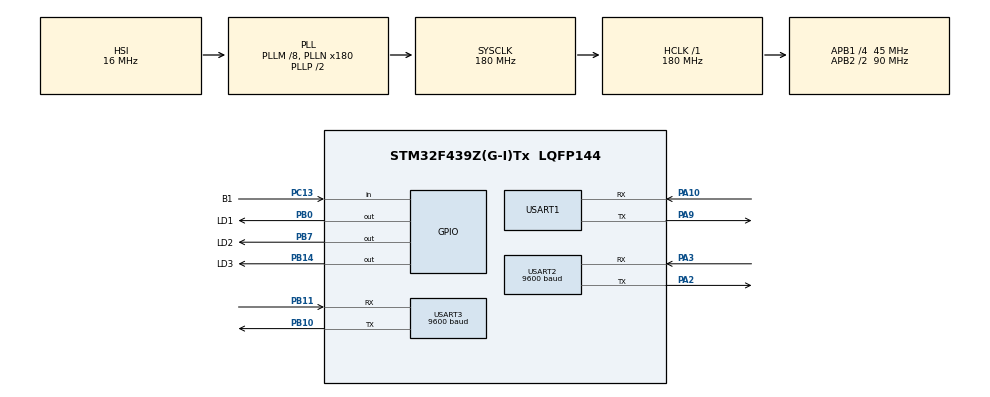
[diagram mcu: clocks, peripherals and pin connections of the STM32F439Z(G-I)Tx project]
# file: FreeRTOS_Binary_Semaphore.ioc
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FREERTOS.BinarySemaphores01=BinSem,Dynamic,NULL
FREERTOS.Tasks01=NormalTask,24,128,StartNormalTask,Default,NULL,Dynamic,NULL,NULL;HighTask,32,128,StartHighTask,Default,NULL,Dynamic,NULL,NULL;LowTask,8,128,StartLowTask,Default,NULL,Dynamic,NULL,NULL
Mcu.Family=STM32F4
Mcu.Name=STM32F439Z(G-I)Tx
Mcu.Package=LQFP144
NVIC.PriorityGroup=NVIC_PRIORITYGROUP_4
NVIC.TIM6_DAC_IRQn=true\:0\:0\:false\:false\:true\:false\:false\:true
NVIC.TimeBase=TIM6_DAC_IRQn
NVIC.TimeBaseIP=TIM6
PA10.Mode=Asynchronous
PA10.Signal=USART1_RX
PA2.Mode=Asynchronous
PA2.Signal=USART2_TX
PA3.Mode=Asynchronous
PA3.Signal=USART2_RX
PA9.Mode=Asynchronous
PA9.Signal=USART1_TX
PB0.GPIO_Label=LD1
PB0.Signal=GPIO_Output
PB10.Mode=Asynchronous
PB10.Signal=USART3_TX
PB11.Mode=Asynchronous
PB11.Signal=USART3_RX
PB14.GPIO_Label=LD3
PB14.Signal=GPIO_Output
PB7.GPIO_Label=LD2
PB7.Signal=GPIO_Output
PC13.GPIO_Label=B1
PC13.Signal=GPIO_Input
PH0/OSC_IN.Mode=HSE-External-Oscillator
PH0/OSC_IN.Signal=RCC_OSC_IN
PH1/OSC_OUT.Mode=HSE-External-Oscillator
PH1/OSC_OUT.Signal=RCC_OSC_OUT
ProjectManager.HeapSize=0x200
ProjectManager.StackSize=0x400
ProjectManager.TargetToolchain=STM32CubeIDE
RCC.48MHZClocksFreq_Value=90000000
RCC.AHBFreq_Value=180000000
RCC.APB1CLKDivider=RCC_HCLK_DIV4
RCC.APB1Freq_Value=45000000
RCC.APB1TimFreq_Value=90000000
RCC.APB2CLKDivider=RCC_HCLK_DIV2
RCC.APB2Freq_Value=90000000
RCC.APB2TimFreq_Value=180000000
RCC.CortexFreq_Value=180000000
RCC.HCLKFreq_Value=180000000
RCC.HSE_VALUE=25000000
RCC.HSI_VALUE=16000000
RCC.LSE_VALUE=32768
RCC.PLLM=8
RCC.PLLN=180
RCC.SYSCLKFreq_VALUE=180000000
RCC.SYSCLKSource=RCC_SYSCLKSOURCE_PLLCLK
RCC.VCOOutputFreq_Value=360000000
USART1.VirtualMode=VM_ASYNC
USART2.BaudRate=9600
USART2.VirtualMode=VM_ASYNC
USART3.BaudRate=9600
USART3.VirtualMode=VM_ASYNC
VP_FREERTOS_VS_CMSIS_V2.Mode=CMSIS_V2
VP_SYS_VS_tim6.Mode=TIM6
board=custom

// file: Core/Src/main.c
/* USER CODE BEGIN Header */
/**
  ******************************************************************************
  * @file           : main.c
  * @brief          : Main program body
  ******************************************************************************
  * @attention
  *
  * <h2><center>&copy; Copyright (c) 2021 STMicroelectronics.
  * All rights reserved.</center></h2>
  *
  * This software component is licensed by ST under BSD 3-Clause license,
  * the "License"; You may not use this file except in compliance with the
  * License. You may obtain a copy of the License at:
  *                        opensource.org/licenses/BSD-3-Clause
  *
  ******************************************************************************
  */
/* USER CODE END Header */

#include "main.h"
#include "cmsis_os.h"

/* USER CODE BEGIN Includes */
#include <string.h>
/* USER CODE END Includes */

UART_HandleTypeDef huart1;
UART_HandleTypeDef huart2;
UART_HandleTypeDef huart3;

/* Definitions for NormalTask */
osThreadId_t NormalTaskHandle;
const osThreadAttr_t NormalTask_attributes = {
  .name = "NormalTask",
  .priority = (osPriority_t) osPriorityNormal,
  .stack_size = 128 * 4
};
/* Definitions for HighTask */
osThreadId_t HighTaskHandle;
const osThreadAttr_t HighTask_attributes = {
  .name = "HighTask",
  .priority = (osPriority_t) osPriorityAboveNormal,
  .stack_size = 128 * 4
};
/* Definitions for LowTask */
osThreadId_t LowTaskHandle;
const osThreadAttr_t LowTask_attributes = {
  .name = "LowTask",
  .priority = (osPriority_t) osPriorityLow,
  .stack_size = 128 * 4
};
/* Definitions for BinSem */
osSemaphoreId_t BinSemHandle;
const osSemaphoreAttr_t BinSem_attributes = {
  .name = "BinSem"
};

void SystemClock_Config(void);
static void MX_GPIO_Init(void);
static void MX_USART2_UART_Init(void);
static void MX_USART3_UART_Init(void);
static void MX_USART1_UART_Init(void);
void StartNormalTask(void *argument);
void StartHighTask(void *argument);
void StartLowTask(void *argument);

int main(void)
{

  /* MCU Configuration--------------------------------------------------------*/

  /* Reset of all peripherals, Initializes the Flash interface and the Systick. */
  HAL_Init();

  /* Configure the system clock */
  SystemClock_Config();

  /* Initialize all configured peripherals */
  MX_GPIO_Init();
  MX_USART2_UART_Init();
  MX_USART3_UART_Init();
  MX_USART1_UART_Init();

  /* Init scheduler */
  osKernelInitialize();

  /* Create the semaphores(s) */
  /* creation of BinSem */
  BinSemHandle = osSemaphoreNew(1, 1, &BinSem_attributes);

  /* Create the thread(s) */
  /* creation of NormalTask */
  NormalTaskHandle = osThreadNew(StartNormalTask, NULL, &NormalTask_attributes);

  /* creation of HighTask */
  HighTaskHandle = osThreadNew(StartHighTask, NULL, &HighTask_attributes);

  /* creation of LowTask */
  LowTaskHandle = osThreadNew(StartLowTask, NULL, &LowTask_attributes);

  /* Start scheduler */
  osKernelStart();

  /* We should never get here as control is now taken by the scheduler */
  /* Infinite loop */
  while (1)
  {

  }
}

void SystemClock_Config(void)
{
  RCC_OscInitTypeDef RCC_OscInitStruct = {0};
  RCC_ClkInitTypeDef RCC_ClkInitStruct = {0};

  /** Configure the main internal regulator output voltage
  */
  __HAL_RCC_PWR_CLK_ENABLE();
  __HAL_PWR_VOLTAGESCALING_CONFIG(PWR_REGULATOR_VOLTAGE_SCALE1);
  /** Initializes the CPU, AHB and APB busses clocks
  */
  RCC_OscInitStruct.OscillatorType = RCC_OSCILLATORTYPE_HSI;
  RCC_OscInitStruct.HSIState = RCC_HSI_ON;
  RCC_OscInitStruct.HSICalibrationValue = RCC_HSICALIBRATION_DEFAULT;
  RCC_OscInitStruct.PLL.PLLState = RCC_PLL_ON;
  RCC_OscInitStruct.PLL.PLLSource = RCC_PLLSOURCE_HSI;
  RCC_OscInitStruct.PLL.PLLM = 8;
  RCC_OscInitStruct.PLL.PLLN = 180;
  RCC_OscInitStruct.PLL.PLLP = RCC_PLLP_DIV2;
  RCC_OscInitStruct.PLL.PLLQ = 4;
  if (HAL_RCC_OscConfig(&RCC_OscInitStruct) != HAL_OK)
  {
    Error_Handler();
  }
  /** Activate the Over-Drive mode
  */
  if (HAL_PWREx_EnableOverDrive() != HAL_OK)
  {
    Error_Handler();
  }
  /** Initializes the CPU, AHB and APB busses clocks
  */
  RCC_ClkInitStruct.ClockType = RCC_CLOCKTYPE_HCLK|RCC_CLOCKTYPE_SYSCLK
                              |RCC_CLOCKTYPE_PCLK1|RCC_CLOCKTYPE_PCLK2;
  RCC_ClkInitStruct.SYSCLKSource = RCC_SYSCLKSOURCE_PLLCLK;
  RCC_ClkInitStruct.AHBCLKDivider = RCC_SYSCLK_DIV1;
  RCC_ClkInitStruct.APB1CLKDivider = RCC_HCLK_DIV4;
  RCC_ClkInitStruct.APB2CLKDivider = RCC_HCLK_DIV2;

  if (HAL_RCC_ClockConfig(&RCC_ClkInitStruct, FLASH_LATENCY_5) != HAL_OK)
  {
    Error_Handler();
  }
}

static void MX_USART1_UART_Init(void)
{

  huart1.Instance = USART1;
  huart1.Init.BaudRate = 115200;
  huart1.Init.WordLength = UART_WORDLENGTH_8B;
  huart1.Init.StopBits = UART_STOPBITS_1;
  huart1.Init.Parity = UART_PARITY_NONE;
  huart1.Init.Mode = UART_MODE_TX_RX;
  huart1.Init.HwFlowCtl = UART_HWCONTROL_NONE;
  huart1.Init.OverSampling = UART_OVERSAMPLING_16;
  if (HAL_UART_Init(&huart1) != HAL_OK)
  {
    Error_Handler();
  }

}

static void MX_USART2_UART_Init(void)
{

  huart2.Instance = USART2;
  huart2.Init.BaudRate = 9600;
  huart2.Init.WordLength = UART_WORDLENGTH_8B;
  huart2.Init.StopBits = UART_STOPBITS_1;
  huart2.Init.Parity = UART_PARITY_NONE;
  huart2.Init.Mode = UART_MODE_TX_RX;
  huart2.Init.HwFlowCtl = UART_HWCONTROL_NONE;
  huart2.Init.OverSampling = UART_OVERSAMPLING_16;
  if (HAL_UART_Init(&huart2) != HAL_OK)
  {
    Error_Handler();
  }

}

static void MX_USART3_UART_Init(void)
{

  huart3.Instance = USART3;
  huart3.Init.BaudRate = 9600;
  huart3.Init.WordLength = UART_WORDLENGTH_8B;
  huart3.Init.StopBits = UART_STOPBITS_1;
  huart3.Init.Parity = UART_PARITY_NONE;
  huart3.Init.Mode = UART_MODE_TX_RX;
  huart3.Init.HwFlowCtl = UART_HWCONTROL_NONE;
  huart3.Init.OverSampling = UART_OVERSAMPLING_16;
  if (HAL_UART_Init(&huart3) != HAL_OK)
  {
    Error_Handler();
  }

}

static void MX_GPIO_Init(void)
{
  GPIO_InitTypeDef GPIO_InitStruct = {0};

  /* GPIO Ports Clock Enable */
  __HAL_RCC_GPIOC_CLK_ENABLE();
  __HAL_RCC_GPIOH_CLK_ENABLE();
  __HAL_RCC_GPIOA_CLK_ENABLE();
  __HAL_RCC_GPIOB_CLK_ENABLE();

  /*Configure GPIO pin Output Level */
  HAL_GPIO_WritePin(GPIOB, LD1_Pin|LD3_Pin|LD2_Pin, GPIO_PIN_RESET);

  /*Configure GPIO pin : B1_Pin */
  GPIO_InitStruct.Pin = B1_Pin;
  GPIO_InitStruct.Mode = GPIO_MODE_INPUT;
  GPIO_InitStruct.Pull = GPIO_NOPULL;
  HAL_GPIO_Init(B1_GPIO_Port, &GPIO_InitStruct);

  /*Configure GPIO pins : LD1_Pin LD3_Pin LD2_Pin */
  GPIO_InitStruct.Pin = LD1_Pin|LD3_Pin|LD2_Pin;
  GPIO_InitStruct.Mode = GPIO_MODE_OUTPUT_PP;
  GPIO_InitStruct.Pull = GPIO_NOPULL;
  GPIO_InitStruct.Speed = GPIO_SPEED_FREQ_LOW;
  HAL_GPIO_Init(GPIOB, &GPIO_InitStruct);

}

void StartNormalTask(void *argument)
{
  /* USER CODE BEGIN 5 */
  /* Infinite loop */
  for(;;)
  {
	  	osDelay(200);
	    HAL_GPIO_WritePin(GPIOB, LD2_Pin, 0);
	    osDelay(200);
	    HAL_GPIO_WritePin(GPIOB, LD2_Pin, 1);

  }
  /* USER CODE END 5 */
}

void StartHighTask(void *argument)
{
  /* USER CODE BEGIN StartHighTask */
  /* Infinite loop */
  for(;;)
  {
	    osDelay(400);
	    HAL_GPIO_WritePin(GPIOB, LD3_Pin, 0);
	    osDelay(400);
	    HAL_GPIO_WritePin(GPIOB, LD3_Pin, 1);
  }
  /* USER CODE END StartHighTask */
}

void StartLowTask(void *argument)
{
  /* USER CODE BEGIN StartLowTask */
  /* Infinite loop */
  for(;;)
  {
	  	osDelay(100);
	    HAL_GPIO_WritePin(GPIOB, LD1_Pin, 0);
	    osDelay(100);
	    HAL_GPIO_WritePin(GPIOB, LD1_Pin, 1);
  }
  /* USER CODE END StartLowTask */
}

 /**
  * @brief  Period elapsed callback in non blocking mode
  * @note   This function is called  when TIM6 interrupt took place, inside
  * HAL_TIM_IRQHandler(). It makes a direct call to HAL_IncTick() to increment
  * a global variable "uwTick" used as application time base.
  * @param  htim : TIM handle
  * @retval None
  */
void HAL_TIM_PeriodElapsedCallback(TIM_HandleTypeDef *htim)
{
  if (htim->Instance == TIM6) {
    HAL_IncTick();
  }
}

void Error_Handler(void)
{
}

/************************ (C) COPYRIGHT STMicroelectronics *****END OF FILE****/
